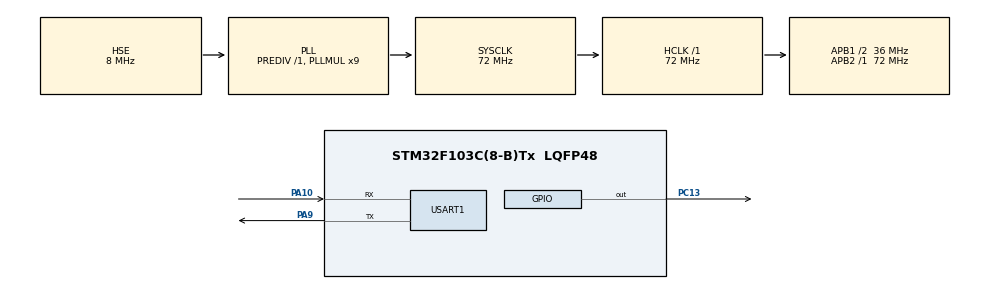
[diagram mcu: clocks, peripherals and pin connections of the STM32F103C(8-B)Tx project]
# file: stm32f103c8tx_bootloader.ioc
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Mcu.Family=STM32F1
Mcu.Name=STM32F103C(8-B)Tx
Mcu.Package=LQFP48
NVIC.PriorityGroup=NVIC_PRIORITYGROUP_4
NVIC.USART1_IRQn=true\:0\:0\:false\:false\:true\:true\:true
PA10.Mode=Asynchronous
PA10.Signal=USART1_RX
PA9.Mode=Asynchronous
PA9.Signal=USART1_TX
PC13-TAMPER-RTC.GPIO_Speed=GPIO_SPEED_FREQ_HIGH
PC13-TAMPER-RTC.PinState=GPIO_PIN_SET
PC13-TAMPER-RTC.Signal=GPIO_Output
PD0-OSC_IN.Mode=HSE-External-Oscillator
PD0-OSC_IN.Signal=RCC_OSC_IN
PD1-OSC_OUT.Mode=HSE-External-Oscillator
PD1-OSC_OUT.Signal=RCC_OSC_OUT
ProjectManager.HeapSize=0x200
ProjectManager.StackSize=0x400
ProjectManager.TargetToolchain=TrueSTUDIO
RCC.AHBFreq_Value=72000000
RCC.APB1CLKDivider=RCC_HCLK_DIV2
RCC.APB1Freq_Value=36000000
RCC.APB1TimFreq_Value=72000000
RCC.APB2Freq_Value=72000000
RCC.APB2TimFreq_Value=72000000
RCC.HCLKFreq_Value=72000000
RCC.PLLMUL=RCC_PLL_MUL9
RCC.PLLSourceVirtual=RCC_PLLSOURCE_HSE
RCC.SYSCLKFreq_VALUE=72000000
RCC.SYSCLKSource=RCC_SYSCLKSOURCE_PLLCLK
RCC.USBFreq_Value=72000000
USART1.VirtualMode=VM_ASYNC
VP_SYS_VS_ND.Mode=No_Debug
board=custom

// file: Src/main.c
#include <stdio.h>
#include <stdlib.h>
#include <string.h>
#include <stdbool.h>
#include "main.h"

#define DATA_END_LINE_UART_COUNT		4
#define DATA_END_LINE_UART				0xFF

//typedef enum _data_line_status_
//{
//	DATA_IS_COMPLETE_FOR_LINE ,
//	DATA_IS_NOT_COMPLETE
//}DATA_LINE_STATUS;

UART_HandleTypeDef huart1;

typedef struct _data_uart_app_
{
  bool data_prog_flag;
  uint8_t data_end_count;
  uint16_t data_count;
  uint8_t data_colectt[DATA_FILE_RAW_DATA_LEN + 4];
}DATA_UART_APP;

DATA_FILE data_prog;

DATA_UART_APP uart_app;

uint8_t data_uart;
void SystemClock_Config(void);
static void MX_GPIO_Init(void);
static void MX_USART1_UART_Init(void);
/* USER CODE BEGIN PFP */
HAL_StatusTypeDef UART_Trasnmit_Str(char *str);
void UART_handle_revice_data(uint8_t data_chr);

/* USER CODE BEGIN ET */

/* USER CODE BEGIN PD */

int boot_main(void)
{

  /* MCU Configuration--------------------------------------------------------*/

  /* Reset of all peripherals, Initializes the Flash interface and the Systick. */
  HAL_Init();

  /* Configure the system clock */
  SystemClock_Config();

  /* Initialize all configured peripherals */
  MX_GPIO_Init();
  MX_USART1_UART_Init();

  data_prog.add_flash = 0;
  data_prog.data_len  = 0;
  uart_app.data_prog_flag = false;
  uart_app.data_count = 0;
  uart_app.data_end_count = 0;
  memset(uart_app.data_colectt, 0xFF, DATA_FILE_RAW_DATA_LEN + 4);
  /* USER CODE BEGIN 2 */
  UART_Trasnmit_Str("MCU IS READY TO BOOT");
  HAL_UART_Receive_IT(&huart1, &data_uart, 1);
  /* USER CODE END 2 */
  if(BOOT_erase(APPLICATION_ADDRESS_PRO, APPLICATION_FLASH_LEN) == HAL_OK)
  {
	  UART_Trasnmit_Str("MCU finish to prepare flash memory");
  }
  else
  {
	  UART_Trasnmit_Str("ERROR");
	  return 0;
  }
  /* Infinite loop */
  while (1)
  {

  }
}

void HAL_UART_RxCpltCallback(UART_HandleTypeDef *huart)
{

	if(huart->Instance == huart1.Instance)
	{
    if(uart_app.data_prog_flag == true)
    {
      UART_handle_revice_data(data_uart);
    }
    else
    {
        switch(data_uart)
        {
          case PC_DATA_PROG:
              uart_app.data_prog_flag = true;
              UART_Trasnmit_Str("OK");
              break;

          case PC_COMMAND_JUMP_APP:
        	  uart_app.data_prog_flag = false;
        	  UART_Trasnmit_Str("OK");
              BOOT_jump_app(APPLICATION_ADDRESS_PRO);
              break;

          default:
              break;
        }
    }

		HAL_UART_Receive_IT(&huart1, &data_uart, 1);
	}
}

void UART_handle_revice_data(uint8_t data_chr)
{
	uint8_t idx_data;
	if(data_chr == DATA_END_LINE_UART)
	{
		uart_app.data_end_count++;
		if(uart_app.data_end_count == DATA_END_LINE_UART_COUNT)
		{
			uart_app.data_count = 0;
			if(BOOT_check_data(uart_app.data_colectt) == BOOT_PROCESS_SUCCESS)
			{
				BOOT_handle_data(uart_app.data_colectt, &data_prog);
				BOOT_flash_prog(data_prog);
				data_prog.add_flash = 0;
				data_prog.data_len  = 0;
				UART_Trasnmit_Str("OK");
			}
			else
			{
				UART_Trasnmit_Str("FAIL");
			}
      uart_app.data_prog_flag = false;
      uart_app.data_count = 0;
      uart_app.data_end_count = 0;
      memset(uart_app.data_colectt, 0xFF, DATA_FILE_RAW_DATA_LEN + 4);
		}
	}
	else
	{
		for(idx_data = 0; idx_data < uart_app.data_end_count; idx_data++)
		{
			uart_app.data_colectt[uart_app.data_count + idx_data] = DATA_END_LINE_UART;
		}

		uart_app.data_colectt[uart_app.data_count + uart_app.data_end_count] = data_chr;

		uart_app.data_count = uart_app.data_count + uart_app.data_end_count + 1;
		uart_app.data_end_count = 0;

		if(uart_app.data_count > DATA_FILE_RAW_DATA_LEN + 4)
		{
			while(HAL_OK != UART_Trasnmit_Str("FAIL"));
			uart_app.data_prog_flag = false;
			uart_app.data_count = 0;
			uart_app.data_end_count = 0;
			memset(uart_app.data_colectt, 0xFF, DATA_FILE_RAW_DATA_LEN + 4);
		}
	}
}
void SystemClock_Config(void)
{
  RCC_OscInitTypeDef RCC_OscInitStruct = {0};
  RCC_ClkInitTypeDef RCC_ClkInitStruct = {0};

  /** Initializes the CPU, AHB and APB busses clocks
  */
  RCC_OscInitStruct.OscillatorType = RCC_OSCILLATORTYPE_HSE;
  RCC_OscInitStruct.HSEState = RCC_HSE_ON;
  RCC_OscInitStruct.HSEPredivValue = RCC_HSE_PREDIV_DIV1;
  RCC_OscInitStruct.HSIState = RCC_HSI_ON;
  RCC_OscInitStruct.PLL.PLLState = RCC_PLL_ON;
  RCC_OscInitStruct.PLL.PLLSource = RCC_PLLSOURCE_HSE;
  RCC_OscInitStruct.PLL.PLLMUL = RCC_PLL_MUL9;
  if (HAL_RCC_OscConfig(&RCC_OscInitStruct) != HAL_OK)
  {
    Error_Handler();
  }
  /** Initializes the CPU, AHB and APB busses clocks
  */
  RCC_ClkInitStruct.ClockType = RCC_CLOCKTYPE_HCLK|RCC_CLOCKTYPE_SYSCLK
                              |RCC_CLOCKTYPE_PCLK1|RCC_CLOCKTYPE_PCLK2;
  RCC_ClkInitStruct.SYSCLKSource = RCC_SYSCLKSOURCE_PLLCLK;
  RCC_ClkInitStruct.AHBCLKDivider = RCC_SYSCLK_DIV1;
  RCC_ClkInitStruct.APB1CLKDivider = RCC_HCLK_DIV2;
  RCC_ClkInitStruct.APB2CLKDivider = RCC_HCLK_DIV1;

  if (HAL_RCC_ClockConfig(&RCC_ClkInitStruct, FLASH_LATENCY_2) != HAL_OK)
  {
    Error_Handler();
  }
}

static void MX_USART1_UART_Init(void)
{

  huart1.Instance = USART1;
  huart1.Init.BaudRate = 115200;
  huart1.Init.WordLength = UART_WORDLENGTH_8B;
  huart1.Init.StopBits = UART_STOPBITS_1;
  huart1.Init.Parity = UART_PARITY_NONE;
  huart1.Init.Mode = UART_MODE_TX_RX;
  huart1.Init.HwFlowCtl = UART_HWCONTROL_NONE;
  huart1.Init.OverSampling = UART_OVERSAMPLING_16;
  if (HAL_UART_Init(&huart1) != HAL_OK)
  {
    Error_Handler();
  }

}

static void MX_GPIO_Init(void)
{
  GPIO_InitTypeDef GPIO_InitStruct = {0};

  /* GPIO Ports Clock Enable */
  __HAL_RCC_GPIOC_CLK_ENABLE();
  __HAL_RCC_GPIOD_CLK_ENABLE();
  __HAL_RCC_GPIOA_CLK_ENABLE();

  /*Configure GPIO pin Output Level */
  HAL_GPIO_WritePin(GPIOC, GPIO_PIN_13, GPIO_PIN_SET);

  /*Configure GPIO pin : PC13 */
  GPIO_InitStruct.Pin = GPIO_PIN_13;
  GPIO_InitStruct.Mode = GPIO_MODE_OUTPUT_PP;
  GPIO_InitStruct.Pull = GPIO_NOPULL;
  GPIO_InitStruct.Speed = GPIO_SPEED_FREQ_HIGH;
  HAL_GPIO_Init(GPIOC, &GPIO_InitStruct);

}

/* USER CODE BEGIN 4 */
/*This function is handle jump to application process*/
HAL_StatusTypeDef UART_Trasnmit_Str(char *str)
{
	uint16_t str_len = (uint16_t)strlen(str);
	return (HAL_UART_Transmit_IT(&huart1, (uint8_t *)str, str_len));
}
/* USER CODE END 4 */

void Error_Handler(void)
{
}

/************************ (C) COPYRIGHT STMicroelectronics *****END OF FILE****/
